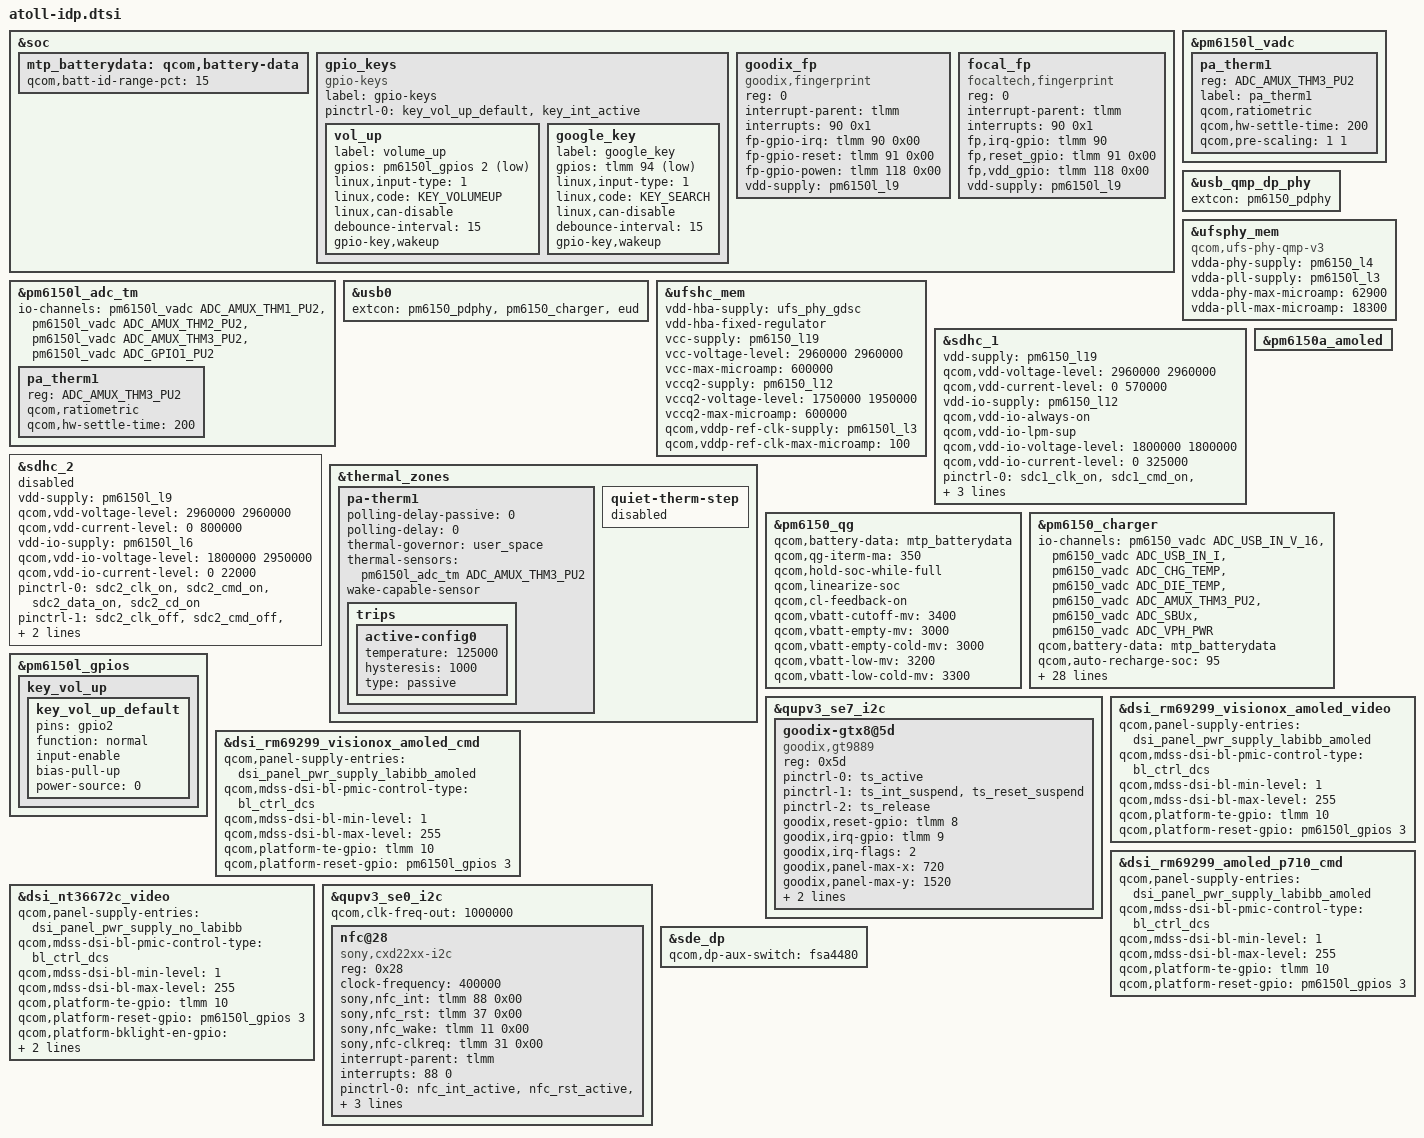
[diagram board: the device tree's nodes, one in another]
/* Copyright (c) 2019-2020, The Linux Foundation. All rights reserved.
 *
 * This program is free software; you can redistribute it and/or modify
 * it under the terms of the GNU General Public License version 2 and
 * only version 2 as published by the Free Software Foundation.
 *
 * This program is distributed in the hope that it will be useful,
 * but WITHOUT ANY WARRANTY; without even the implied warranty of
 * MERCHANTABILITY or FITNESS FOR A PARTICULAR PURPOSE.  See the
 * GNU General Public License for more details.
 */

#include <dt-bindings/gpio/gpio.h>
#include <dt-bindings/pinctrl/qcom,pmic-gpio.h>
#include <dt-bindings/iio/qcom,spmi-vadc.h>
#include <dt-bindings/input/input.h>
#include "atoll-sde-display.dtsi"
#include "atoll-camera-sensor-idp.dtsi"
#include "sdmmagpie-thermal-overlay.dtsi"

&soc {
	mtp_batterydata: qcom,battery-data {
		qcom,batt-id-range-pct = <15>;
		#include "qg-batterydata-2750mah-p710-wk.dtsi"
	};
};

&pm6150l_vadc {
	pa_therm1 {
		reg = <ADC_AMUX_THM3_PU2>;
		label = "pa_therm1";
		qcom,ratiometric;
		qcom,hw-settle-time = <200>;
		qcom,pre-scaling = <1 1>;
	};
};

&pm6150l_adc_tm {
	io-channels = <&pm6150l_vadc ADC_AMUX_THM1_PU2>,
			<&pm6150l_vadc ADC_AMUX_THM2_PU2>,
			<&pm6150l_vadc ADC_AMUX_THM3_PU2>,
			<&pm6150l_vadc ADC_GPIO1_PU2>;

	pa_therm1 {
		reg = <ADC_AMUX_THM3_PU2>;
		qcom,ratiometric;
		qcom,hw-settle-time = <200>;
	};
};

&usb0 {
	extcon = <&pm6150_pdphy>, <&pm6150_charger>, <&eud>;
};

&usb_qmp_dp_phy {
	extcon = <&pm6150_pdphy>;
};

&ufsphy_mem {
	compatible = "qcom,ufs-phy-qmp-v3";

	vdda-phy-supply = <&pm6150_l4>; /* 0.9v */
	vdda-pll-supply = <&pm6150l_l3>; /* 1.2v */
	vdda-phy-max-microamp = <62900>;
	vdda-pll-max-microamp = <18300>;

	status = "ok";
};

&ufshc_mem {
	vdd-hba-supply = <&ufs_phy_gdsc>;
	vdd-hba-fixed-regulator;
	vcc-supply = <&pm6150_l19>;
	vcc-voltage-level = <2960000 2960000>;
	vcc-max-microamp = <600000>;
	vccq2-supply = <&pm6150_l12>;
	vccq2-voltage-level = <1750000 1950000>;
	vccq2-max-microamp = <600000>;

	qcom,vddp-ref-clk-supply = <&pm6150l_l3>; /* PX10 */
	qcom,vddp-ref-clk-max-microamp = <100>;

	status = "ok";
};

&sdhc_1 {
	vdd-supply = <&pm6150_l19>;
	qcom,vdd-voltage-level = <2960000 2960000>;
	qcom,vdd-current-level = <0 570000>;

	vdd-io-supply = <&pm6150_l12>;
	qcom,vdd-io-always-on;
	qcom,vdd-io-lpm-sup;
	qcom,vdd-io-voltage-level = <1800000 1800000>;
	qcom,vdd-io-current-level = <0 325000>;

	pinctrl-names = "active", "sleep";
	pinctrl-0 = <&sdc1_clk_on &sdc1_cmd_on &sdc1_data_on &sdc1_rclk_on>;
	pinctrl-1 = <&sdc1_clk_off &sdc1_cmd_off &sdc1_data_off &sdc1_rclk_off>;

	status = "ok";
};

&sdhc_2 {
	vdd-supply = <&pm6150l_l9>;
	qcom,vdd-voltage-level = <2960000 2960000>;
	qcom,vdd-current-level = <0 800000>;

	vdd-io-supply = <&pm6150l_l6>;
	qcom,vdd-io-voltage-level = <1800000 2950000>;
	qcom,vdd-io-current-level = <0 22000>;

	pinctrl-names = "active", "sleep";
	pinctrl-0 = <&sdc2_clk_on  &sdc2_cmd_on &sdc2_data_on &sdc2_cd_on>;
	pinctrl-1 = <&sdc2_clk_off &sdc2_cmd_off &sdc2_data_off &sdc2_cd_off>;

	cd-gpios = <&tlmm 69 GPIO_ACTIVE_LOW>;

	status = "disabled";
};

&thermal_zones {
	pa-therm1 {
		polling-delay-passive = <0>;
		polling-delay = <0>;
		thermal-governor = "user_space";
		thermal-sensors = <&pm6150l_adc_tm ADC_AMUX_THM3_PU2>;
		wake-capable-sensor;
		trips {
			active-config0 {
				temperature = <125000>;
				hysteresis = <1000>;
				type = "passive";
			};
		};
	};

	quiet-therm-step {
		status = "disabled";
	};
};

&pm6150a_amoled {
	status = "ok";
};

&pm6150_qg {
	qcom,battery-data = <&mtp_batterydata>;
	qcom,qg-iterm-ma = <350>;
	qcom,hold-soc-while-full;
	qcom,linearize-soc;
	qcom,cl-feedback-on;

	// pony.ma, DATE20200423, qg config, DATE20200423-01 START
	qcom,vbatt-cutoff-mv = <3400>;
	qcom,vbatt-empty-mv = <3000>;
	qcom,vbatt-empty-cold-mv = <3000>;
	qcom,vbatt-low-mv = <3200>;
	qcom,vbatt-low-cold-mv = <3300>;
	// pony.ma, DATE20200423-01 END
};

&pm6150_charger {
	io-channels = <&pm6150_vadc ADC_USB_IN_V_16>,
		      <&pm6150_vadc ADC_USB_IN_I>,
		      <&pm6150_vadc ADC_CHG_TEMP>,
		      <&pm6150_vadc ADC_DIE_TEMP>,
		      <&pm6150_vadc ADC_AMUX_THM3_PU2>,
		      <&pm6150_vadc ADC_SBUx>,
		      <&pm6150_vadc ADC_VPH_PWR>;
	io-channel-names = "usb_in_voltage",
			   "usb_in_current",
			   "chg_temp",
			   "die_temp",
			   "conn_temp",
			   "sbux_res",
			   "vph_voltage";
	qcom,battery-data = <&mtp_batterydata>;
	qcom,auto-recharge-soc = <95>;
	qcom,step-charging-enable;
	qcom,sw-jeita-enable;
	qcom,fcc-stepping-enable;
	qcom,suspend-input-on-debug-batt;
	qcom,sec-charger-config = <0>;       // pony.ma, 0:No secondary charger,1:SMB1390,2:SMB1355, DATE20200423
	qcom,thermal-mitigation = <2000000 1800000 1500000
			1200000 1000000 800000 500000 300000 200000>;   	//8:usb_icl for thermal by pony date20200925
	dpdm-supply = <&qusb_phy0>;
	qcom,charger-temp-max = <800>;
	qcom,smb-temp-max = <800>;
	qcom,fcc-step-delay-ms = <100>;
	qcom,fcc-step-size-ua = <100000>;
	qcom,disable-sw-thermal-regulation;
	qcom,disable-fcc-restriction;
	qcom,smb-internal-pull-kohm = <0>;

	// pony.ma, date20200423, charge config, date20200423-01 START
	qcom,hvdcp-disable;
	qcom,fcc-max-ua = <2000000>;   	//fast current charge in battery profile config
	qcom,usb-icl-ua = <1950000>;	//usb input limit
	qcom,fv-max-uv = <4400000>;		//float voltage in battery profile config
	qcom,otg-cl-ua = <500000>;		//otg limit current
	qcom,float-option = <1>;		//1,DCP;2,SDP;3,disable charging;4,suspend usb input
	qcom,dcp-icl-en = <1>;
	qcom,dcp-icl-ua-1 = <2100000>;
	qcom,float-icl-ua = <1000000>;
	qcom,chg-term-src = <1>;		//tcc config
	qcom,chg-term-current-ma = <(-150)>;	//tcc is 150mA
	qcom,speed-current = <2000000 1800000
				1600000 1400000
				1200000 1000000
				700000  500000
				400000  0>;			//for scc by pony date20200618
	// pony.ma, date20200423-01 END
};

&pm6150l_gpios {
	key_vol_up {
		key_vol_up_default: key_vol_up_default {
			pins = "gpio2";
			function = "normal";
			input-enable;
			bias-pull-up;
			power-source = <0>;
		};
	};
};

&soc {
	gpio_keys {
		compatible = "gpio-keys";
		label = "gpio-keys";

		pinctrl-names = "default";
		pinctrl-0 = <&key_vol_up_default &key_int_active>;

		vol_up {
			label = "volume_up";
			gpios = <&pm6150l_gpios 2 GPIO_ACTIVE_LOW>;
			linux,input-type = <1>;
			linux,code = <KEY_VOLUMEUP>;
			linux,can-disable;
			debounce-interval = <15>;
			gpio-key,wakeup;
		};

		google_key {
			label = "google_key";
			//interrupt-parent = <&tlmm>;
			//interrupts = <94 0x8>;
			gpios = <&tlmm 94 GPIO_ACTIVE_LOW>;
			linux,input-type = <1>;
			linux,code = <KEY_SEARCH>;
			linux,can-disable;
			debounce-interval = <15>;
			gpio-key,wakeup;
		};
	};

	//lijian add for fp start

	goodix_fp {
		compatible = "goodix,fingerprint";
		reg = <0>;
		interrupt-parent = <&tlmm>;
		interrupts = <90 0x1>;
		fp-gpio-irq = <&tlmm 90 0x00>;
		fp-gpio-reset = <&tlmm 91 0x00>;
		fp-gpio-powen = <&tlmm 118 0x00>;
		vdd-supply = <&pm6150l_l9>;
		status = "ok";
	};

	focal_fp {
		compatible = "focaltech,fingerprint";
		reg = <0>;
		interrupt-parent = <&tlmm>;
		interrupts = <90 0x1>;
		fp,irq-gpio = <&tlmm 90 0x00>;
		fp,reset_gpio = <&tlmm 91 0x00>;
		fp,vdd_gpio = <&tlmm 118 0x00>;
		vdd-supply = <&pm6150l_l9>;
		status = "ok";
	};
	//lijian add for fp end
};

&qupv3_se7_i2c {
	status = "ok";
//P710 TP bring up, 20200421 start
/*
	qcom,i2c-touch-active = "synaptics,tcm-i2c";
	synaptics_tcm@20 {
		compatible = "synaptics,tcm-i2c";
		reg = <0x20>;
		interrupt-parent = <&tlmm>;
		interrupts = <9 0x2008>;
		pinctrl-names = "pmx_ts_active","pmx_ts_suspend",
			"pmx_ts_release";
		pinctrl-0 = <&ts_active>;
		pinctrl-1 = <&ts_int_suspend &ts_reset_suspend>;
		pinctrl-2 = <&ts_release>;
		vdd-supply = <&pm6150_l10>;
		avdd-supply = <&pm6150l_l7>;
		synaptics,pwr-reg-name = "avdd";
		synaptics,bus-reg-name = "vdd";
		synaptics,irq-gpio = <&tlmm 9 0x2008>;
		synaptics,irq-on-state = <0>;
		synaptics,reset-gpio = <&tlmm 8 0x00>;
		synaptics,reset-on-state = <0>;
		synaptics,reset-active-ms = <20>;
		synaptics,reset-delay-ms = <200>;
		synaptics,power-delay-ms = <200>;
		synaptics,ubl-i2c-addr = <0x20>;
	};

	atmel_mxt_ts@4a {
		compatible = "atmel,maxtouch";
		reg = <0x4a>;
		interrupt-parent = <&tlmm>;
		interrupts = <9 0x2008>;
		avdd-supply = <&pm6150l_l7>;
		vdd-supply = <&pm6150_l10>;
		pinctrl-names = "pmx_ts_active", "pmx_ts_suspend";
		pinctrl-0 = <&ts_active>;
		pinctrl-1 = <&ts_int_suspend &ts_reset_suspend>;

		reset-gpios = <&tlmm 8 0x00>;
		irq-gpios = <&tlmm 9 0x2008>;

		atmel,xy_switch;
		atmel,panel-coords = <0 0 479 799>;
		atmel,display-coords = <0 0 339 769>;
	};
*/
	goodix-gtx8@5d {
		compatible = "goodix,gt9889";
		reg = <0x5d>;
		pinctrl-names = "pmx_ts_active","pmx_ts_suspend",
			"pmx_ts_release";
		pinctrl-0 = <&ts_active>;
		pinctrl-1 = <&ts_int_suspend &ts_reset_suspend>;
		pinctrl-2 = <&ts_release>;
		goodix,reset-gpio = <&tlmm 8 0x00>;
		goodix,irq-gpio = <&tlmm 9 0x2800>;
		goodix,irq-flags = <2>; /* 1:trigger rising, 2:trigger falling;*/
		goodix,panel-max-x = <720>;
		goodix,panel-max-y = <1520>;
		goodix,panel-max-w = <255>;
		goodix,avdd-name = "pm6150l_l7";
		//goodix,x2x;
		//goodix,y2y;
	};
//P710 TP bring up, 20200421 end
};

&dsi_rm69299_visionox_amoled_video {
	qcom,panel-supply-entries = <&dsi_panel_pwr_supply_labibb_amoled>;
	qcom,mdss-dsi-bl-pmic-control-type = "bl_ctrl_dcs";
	qcom,mdss-dsi-bl-min-level = <1>;
	qcom,mdss-dsi-bl-max-level = <255>;
	qcom,platform-te-gpio = <&tlmm 10 0>;
	qcom,platform-reset-gpio = <&pm6150l_gpios 3 0>;
};

&dsi_rm69299_visionox_amoled_cmd {
	qcom,panel-supply-entries = <&dsi_panel_pwr_supply_labibb_amoled>;
	qcom,mdss-dsi-bl-pmic-control-type = "bl_ctrl_dcs";
	qcom,mdss-dsi-bl-min-level = <1>;
	qcom,mdss-dsi-bl-max-level = <255>;
	qcom,platform-te-gpio = <&tlmm 10 0>;
	qcom,platform-reset-gpio = <&pm6150l_gpios 3 0>;
};

//add p710 RM69299 LCD IC begin:
&dsi_rm69299_amoled_p710_cmd {
	qcom,panel-supply-entries = <&dsi_panel_pwr_supply_labibb_amoled>;
	qcom,mdss-dsi-bl-pmic-control-type = "bl_ctrl_dcs";
	qcom,mdss-dsi-bl-min-level = <1>;
	qcom,mdss-dsi-bl-max-level = <255>;
	qcom,platform-te-gpio = <&tlmm 10 0>;
	qcom,platform-reset-gpio = <&pm6150l_gpios 3 0>;
};
//add p710 RM69299 LCD IC end

&dsi_nt36672c_video {
	qcom,panel-supply-entries = <&dsi_panel_pwr_supply_no_labibb>;
	qcom,mdss-dsi-bl-pmic-control-type = "bl_ctrl_dcs";
	qcom,mdss-dsi-bl-min-level = <1>;
	qcom,mdss-dsi-bl-max-level = <255>;
	qcom,platform-te-gpio = <&tlmm 10 0>;
	qcom,platform-reset-gpio = <&pm6150l_gpios 3 0>;
	qcom,platform-bklight-en-gpio = <&pm6150l_gpios 10 0>;
	qcom,platform-en-gpio = <&pm6150l_gpios 4 0>;
};

&qupv3_se0_i2c {
	status = "ok";
	qcom,clk-freq-out = <1000000>;
	#address-cells = <1>;
	#size-cells = <0>;
	nfc@28 {
		compatible = "sony,cxd22xx-i2c";
		status = "ok";
		reg = <0x28>;
		clock-frequency = <400000>;
		sony,nfc_int = <&tlmm 88 0x00>;
		sony,nfc_rst = <&tlmm 37 0x00>;
		sony,nfc_wake = <&tlmm 11 0x00>;
		sony,nfc-clkreq = <&tlmm 31 0x00>;
		interrupt-parent = <&tlmm>;
		interrupts = <88 0>;
		interrupt-names = "nfc_irq";
		pinctrl-names = "nfc_active", "nfc_suspend";
		pinctrl-0 = <&nfc_int_active &nfc_rst_active  &nfc_enable_active
					&nfc_clk_req_active>;
		pinctrl-1 = <&nfc_int_suspend &nfc_rst_suspend &nfc_enable_suspend
					&nfc_clk_req_suspend>;
	};
};

&sde_dp{
	qcom,dp-aux-switch = <&fsa4480>;
};

